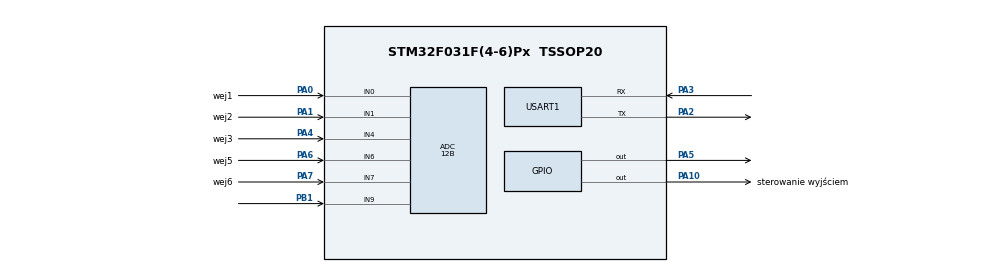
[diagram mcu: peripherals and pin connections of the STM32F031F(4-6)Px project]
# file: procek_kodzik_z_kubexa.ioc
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ADC.ClockPrescaler=ADC_CLOCK_ASYNC_DIV1
ADC.ContinuousConvMode=DISABLE
ADC.DMAContinuousRequests=DISABLE
ADC.DataAlign=ADC_DATAALIGN_RIGHT
ADC.DiscontinuousConvMode=DISABLE
ADC.EOCSelection=ADC_EOC_SINGLE_CONV
ADC.EnableAnalogWatchDog=false
ADC.ExternalTrigConv=ADC_SOFTWARE_START
ADC.ExternalTrigConvEdge=ADC_EXTERNALTRIGCONVEDGE_NONE
ADC.LowPowerAutoPowerOff=DISABLE
ADC.LowPowerAutoWait=DISABLE
ADC.Overrun=ADC_OVR_DATA_PRESERVED
ADC.Resolution=ADC_RESOLUTION_12B
ADC.SamplingTime=ADC_SAMPLETIME_1CYCLE_5
ADC.ScanConvMode=ADC_SCAN_DIRECTION_FORWARD
Mcu.Family=STM32F0
Mcu.Name=STM32F031F(4-6)Px
Mcu.Package=TSSOP20
NVIC.USART1_IRQn=true\:0\:0\:false\:false\:true\:true
PA0.GPIO_Label=wej1
PA0.GPIO_Mode=GPIO_MODE_ANALOG
PA0.GPIO_PuPd=GPIO_NOPULL
PA0.Mode=IN0
PA0.Signal=ADC_IN0
PA1.GPIO_Label=wej2
PA1.Mode=IN1
PA1.Signal=ADC_IN1
PA10.GPIO_Label=sterowanie wyj\u015Bciem
PA10.Signal=GPIO_Output
PA13.Mode=Serial_Wire
PA13.Signal=SYS_SWDIO
PA14.Mode=Serial_Wire
PA14.Signal=SYS_SWCLK
PA2.Mode=Asynchronous
PA2.Signal=USART1_TX
PA3.Mode=Asynchronous
PA3.Signal=USART1_RX
PA4.GPIO_Label=wej3
PA4.Mode=IN4
PA4.Signal=ADC_IN4
PA5.Signal=GPIO_Output
PA6.GPIO_Label=wej5
PA6.Mode=IN6
PA6.Signal=ADC_IN6
PA7.GPIO_Label=wej6
PA7.Mode=IN7
PA7.Signal=ADC_IN7
PB1.Mode=IN9
PB1.Signal=ADC_IN9
PF0-OSC_IN.Mode=HSE-External-Oscillator
PF0-OSC_IN.Signal=RCC_OSC_IN
PF1-OSC_OUT.Mode=HSE-External-Oscillator
PF1-OSC_OUT.Signal=RCC_OSC_OUT
ProjectManager.HeapSize=0x200
ProjectManager.StackSize=0x400
ProjectManager.TargetToolchain=SW4STM32
RCC.AHBFreq_Value=48000000
RCC.APB1Freq_Value=48000000
RCC.APB1TimFreq_Value=48000000
RCC.HCLKFreq_Value=48000000
RCC.PLLMUL=RCC_PLL_MUL6
RCC.PLLSourceVirtual=RCC_PLLSOURCE_HSE
RCC.SYSCLKFreq_VALUE=48000000
RCC.SYSCLKSource=RCC_SYSCLKSOURCE_PLLCLK
USART1.DMADisableonRxErrorParam=ADVFEATURE_DMA_DISABLEONRXERROR
USART1.OverrunDisableParam=ADVFEATURE_OVERRUN_DISABLE
USART1.VirtualMode-Asynchronous=VM_ASYNC
VP_ADC_TempSens_Input.Mode=IN-TempSens
board=custom

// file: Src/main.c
/**
  ******************************************************************************
  * @file           : main.c
  * @brief          : Main program body
  ******************************************************************************
  ** This notice applies to any and all portions of this file
  * that are not between comment pairs USER CODE BEGIN and
  * USER CODE END. Other portions of this file, whether
  * inserted by the user or by software development tools
  * are owned by their respective copyright owners.
  *
  * COPYRIGHT(c) 2018 STMicroelectronics
  *
  * Redistribution and use in source and binary forms, with or without modification,
  * are permitted provided that the following conditions are met:
  *   1. Redistributions of source code must retain the above copyright notice,
  *      this list of conditions and the following disclaimer.
  *   2. Redistributions in binary form must reproduce the above copyright notice,
  *      this list of conditions and the following disclaimer in the documentation
  *      and/or other materials provided with the distribution.
  *   3. Neither the name of STMicroelectronics nor the names of its contributors
  *      may be used to endorse or promote products derived from this software
  *      without specific prior written permission.
  *
  * THIS SOFTWARE IS PROVIDED BY THE COPYRIGHT HOLDERS AND CONTRIBUTORS "AS IS"
  * AND ANY EXPRESS OR IMPLIED WARRANTIES, INCLUDING, BUT NOT LIMITED TO, THE
  * IMPLIED WARRANTIES OF MERCHANTABILITY AND FITNESS FOR A PARTICULAR PURPOSE ARE
  * DISCLAIMED. IN NO EVENT SHALL THE COPYRIGHT HOLDER OR CONTRIBUTORS BE LIABLE
  * FOR ANY DIRECT, INDIRECT, INCIDENTAL, SPECIAL, EXEMPLARY, OR CONSEQUENTIAL
  * DAMAGES (INCLUDING, BUT NOT LIMITED TO, PROCUREMENT OF SUBSTITUTE GOODS OR
  * SERVICES; LOSS OF USE, DATA, OR PROFITS; OR BUSINESS INTERRUPTION) HOWEVER
  * CAUSED AND ON ANY THEORY OF LIABILITY, WHETHER IN CONTRACT, STRICT LIABILITY,
  * OR TORT (INCLUDING NEGLIGENCE OR OTHERWISE) ARISING IN ANY WAY OUT OF THE USE
  * OF THIS SOFTWARE, EVEN IF ADVISED OF THE POSSIBILITY OF SUCH DAMAGE.
  *
  ******************************************************************************
  */
#include <komunikacja.h>
#include "main.h"
#include "stm32f0xx_hal.h"

ADC_HandleTypeDef hadc;

UART_HandleTypeDef huart1;

/* USER CODE BEGIN PV */
/* Private variables ---------------------------------------------------------*/

/* USER CODE END PV */

void SystemClock_Config(void);
static void MX_GPIO_Init(void);
static void MX_ADC_Init(void);
static void MX_USART1_UART_Init(void);
uint8_t aTxStartMessage[] = "\r\n****UART-Hyperterminal communication based on IT ****\r\nEnter 10 characters using keyboard :\r\n";

uint8_t aRxBuffer[20];/*bufor transmisji przychodzącej*/
/* USER CODE BEGIN PFP */
/* Private function prototypes -----------------------------------------------*/

/* USER CODE END PFP */

int main(void)

{

  /* MCU Configuration----------------------------------------------------------*/

  /* Reset of all peripherals, Initializes the Flash interface and the Systick. */
  HAL_Init();

  /* Configure the system clock */
  SystemClock_Config();

  /* Initialize all configured peripherals */
  MX_GPIO_Init();
  MX_ADC_Init();
  MX_USART1_UART_Init();
  /* USER CODE BEGIN 2 */
  //HAL_UART_Transmit_IT(&huart1, (uint8_t *)aTxStartMessage, sizeof(aTxStartMessage));
  //HAL_UART_Receive_IT(&huart1, (uint8_t *)aRxBuffer, 1); /*inicjalizacja przerwania od transmisji przychodzącej
 // realizowana jest pojedynczymi znakami zapisywanymi do odpowiedniego bufora*/
  /* USER CODE END 2 */
startUSART();
  /* Infinite loop */
  while (1)
  {

  }

}

  RCC_OscInitStruct.OscillatorType = RCC_OSCILLATORTYPE_HSI14|RCC_OSCILLATORTYPE_HSE;
  RCC_OscInitStruct.HSEState = RCC_HSE_ON;
  RCC_OscInitStruct.HSI14State = RCC_HSI14_ON;
  RCC_OscInitStruct.HSI14CalibrationValue = 16;
  RCC_OscInitStruct.PLL.PLLState = RCC_PLL_ON;
  RCC_OscInitStruct.PLL.PLLSource = RCC_PLLSOURCE_HSE;
  RCC_OscInitStruct.PLL.PLLMUL = RCC_PLL_MUL6;
  RCC_OscInitStruct.PLL.PREDIV = RCC_PREDIV_DIV1;
  if (HAL_RCC_OscConfig(&RCC_OscInitStruct) != HAL_OK)
  {
    _Error_Handler(__FILE__, __LINE__);
  }

    /**Initializes the CPU, AHB and APB busses clocks
    */
  RCC_ClkInitStruct.ClockType = RCC_CLOCKTYPE_HCLK|RCC_CLOCKTYPE_SYSCLK
                              |RCC_CLOCKTYPE_PCLK1;
  RCC_ClkInitStruct.SYSCLKSource = RCC_SYSCLKSOURCE_PLLCLK;
  RCC_ClkInitStruct.AHBCLKDivider = RCC_SYSCLK_DIV1;
  RCC_ClkInitStruct.APB1CLKDivider = RCC_HCLK_DIV1;

  if (HAL_RCC_ClockConfig(&RCC_ClkInitStruct, FLASH_LATENCY_1) != HAL_OK)
  {
    _Error_Handler(__FILE__, __LINE__);
  }

  PeriphClkInit.PeriphClockSelection = RCC_PERIPHCLK_USART1;
  PeriphClkInit.Usart1ClockSelection = RCC_USART1CLKSOURCE_PCLK1;
  if (HAL_RCCEx_PeriphCLKConfig(&PeriphClkInit) != HAL_OK)
  {
    _Error_Handler(__FILE__, __LINE__);
  }

    /**Configure the Systick interrupt time
    */
  HAL_SYSTICK_Config(HAL_RCC_GetHCLKFreq()/1000);

    /**Configure the Systick
    */
  HAL_SYSTICK_CLKSourceConfig(SYSTICK_CLKSOURCE_HCLK);

  /* SysTick_IRQn interrupt configuration */
  HAL_NVIC_SetPriority(SysTick_IRQn, 0, 0);
}

/* ADC init function */
static void MX_ADC_Init(void)
{

  ADC_ChannelConfTypeDef sConfig;

    /**Configure the global features of the ADC (Clock, Resolution, Data Alignment and number of conversion)
    */
  hadc.Instance = ADC1;
  hadc.Init.ClockPrescaler = ADC_CLOCK_ASYNC_DIV1;
  hadc.Init.Resolution = ADC_RESOLUTION_12B;
  hadc.Init.DataAlign = ADC_DATAALIGN_RIGHT;
  hadc.Init.ScanConvMode = ADC_SCAN_DIRECTION_FORWARD;
  hadc.Init.EOCSelection = ADC_EOC_SINGLE_CONV;
  hadc.Init.LowPowerAutoWait = DISABLE;
  hadc.Init.LowPowerAutoPowerOff = DISABLE;
  hadc.Init.ContinuousConvMode = DISABLE;
  hadc.Init.DiscontinuousConvMode = DISABLE;
  hadc.Init.ExternalTrigConv = ADC_SOFTWARE_START;
  hadc.Init.ExternalTrigConvEdge = ADC_EXTERNALTRIGCONVEDGE_NONE;
  hadc.Init.DMAContinuousRequests = DISABLE;
  hadc.Init.Overrun = ADC_OVR_DATA_PRESERVED;
  if (HAL_ADC_Init(&hadc) != HAL_OK)
  {
    _Error_Handler(__FILE__, __LINE__);
  }

    /**Configure for the selected ADC regular channel to be converted.
    */
  sConfig.Channel = ADC_CHANNEL_0;
  sConfig.Rank = ADC_RANK_CHANNEL_NUMBER;
  sConfig.SamplingTime = ADC_SAMPLETIME_1CYCLE_5;
  if (HAL_ADC_ConfigChannel(&hadc, &sConfig) != HAL_OK)
  {
    _Error_Handler(__FILE__, __LINE__);
  }

    /**Configure for the selected ADC regular channel to be converted.
    */
  sConfig.Channel = ADC_CHANNEL_1;
  if (HAL_ADC_ConfigChannel(&hadc, &sConfig) != HAL_OK)
  {
    _Error_Handler(__FILE__, __LINE__);
  }

    /**Configure for the selected ADC regular channel to be converted.
    */
  sConfig.Channel = ADC_CHANNEL_4;
  if (HAL_ADC_ConfigChannel(&hadc, &sConfig) != HAL_OK)
  {
    _Error_Handler(__FILE__, __LINE__);
  }

    /**Configure for the selected ADC regular channel to be converted.
    */
  sConfig.Channel = ADC_CHANNEL_6;
  if (HAL_ADC_ConfigChannel(&hadc, &sConfig) != HAL_OK)
  {
    _Error_Handler(__FILE__, __LINE__);
  }

    /**Configure for the selected ADC regular channel to be converted.
    */
  sConfig.Channel = ADC_CHANNEL_7;
  if (HAL_ADC_ConfigChannel(&hadc, &sConfig) != HAL_OK)
  {
    _Error_Handler(__FILE__, __LINE__);
  }

    /**Configure for the selected ADC regular channel to be converted.
    */
  sConfig.Channel = ADC_CHANNEL_9;
  if (HAL_ADC_ConfigChannel(&hadc, &sConfig) != HAL_OK)
  {
    _Error_Handler(__FILE__, __LINE__);
  }

    /**Configure for the selected ADC regular channel to be converted.
    */
  sConfig.Channel = ADC_CHANNEL_TEMPSENSOR;
  if (HAL_ADC_ConfigChannel(&hadc, &sConfig) != HAL_OK)
  {
    _Error_Handler(__FILE__, __LINE__);
  }

}

/* USART1 init function */
static void MX_USART1_UART_Init(void)
{

  huart1.Instance = USART1;
  huart1.Init.BaudRate = 38400;
  huart1.Init.WordLength = UART_WORDLENGTH_8B;
  huart1.Init.StopBits = UART_STOPBITS_1;
  huart1.Init.Parity = UART_PARITY_NONE;
  huart1.Init.Mode = UART_MODE_TX_RX;
  huart1.Init.HwFlowCtl = UART_HWCONTROL_NONE;
  huart1.Init.OverSampling = UART_OVERSAMPLING_16;
  huart1.Init.OneBitSampling = UART_ONE_BIT_SAMPLE_DISABLE;
  huart1.AdvancedInit.AdvFeatureInit = UART_ADVFEATURE_RXOVERRUNDISABLE_INIT|UART_ADVFEATURE_DMADISABLEONERROR_INIT;
  huart1.AdvancedInit.OverrunDisable = UART_ADVFEATURE_OVERRUN_DISABLE;
  huart1.AdvancedInit.DMADisableonRxError = UART_ADVFEATURE_DMA_DISABLEONRXERROR;
  if (HAL_UART_Init(&huart1) != HAL_OK)
  {
    _Error_Handler(__FILE__, __LINE__);
  }

}

/** Configure pins as
        * Analog
        * Input
        * Output
        * EVENT_OUT
        * EXTI
*/
static void MX_GPIO_Init(void)
{

  GPIO_InitTypeDef GPIO_InitStruct;

  /* GPIO Ports Clock Enable */
  __HAL_RCC_GPIOF_CLK_ENABLE();
  __HAL_RCC_GPIOA_CLK_ENABLE();
  __HAL_RCC_GPIOB_CLK_ENABLE();

  /*Configure GPIO pin Output Level */
  HAL_GPIO_WritePin(GPIOA, GPIO_PIN_5|sterowanie_wyj_ciem_Pin, GPIO_PIN_RESET);

  /*Configure GPIO pins : PA5 sterowanie_wyj_ciem_Pin */
  GPIO_InitStruct.Pin = GPIO_PIN_5|sterowanie_wyj_ciem_Pin;
  GPIO_InitStruct.Mode = GPIO_MODE_OUTPUT_PP;
  GPIO_InitStruct.Pull = GPIO_NOPULL;
  GPIO_InitStruct.Speed = GPIO_SPEED_FREQ_LOW;
  HAL_GPIO_Init(GPIOA, &GPIO_InitStruct);

}

void _Error_Handler(char *file, int line)
{
  while(1)
  {
  }
}

void startUSART()
{
	 /* Enable the UART Parity Error and Data Register not empty Interrupts */
	    SET_BIT(huart1.Instance->CR1, USART_CR1_PEIE | USART_CR1_RXNEIE);
	}

/************************ (C) COPYRIGHT STMicroelectronics *****END OF FILE****/
